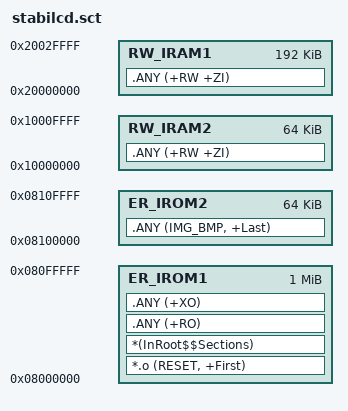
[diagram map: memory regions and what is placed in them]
; *************************************************************
; *** Scatter-Loading Description File generated by uVision ***
; *************************************************************

LR_IROM1 0x08000000 0x00100000  {    ; load region size_region
  ER_IROM1 0x08000000 0x00100000  {  ; load address = execution address
   *.o (RESET, +First)
   *(InRoot$$Sections)
   .ANY (+RO)
   .ANY (+XO)
  }
  ;ER_IROM2 0x08100000 0x00010000  {  ; img
  ; .ANY (IMG_BMP, +Last)
  ;}
  RW_IRAM1 0x20000000 0x00030000  {  ; RW data
   .ANY (+RW +ZI)
  }
  RW_IRAM2 0x10000000 0x00010000  {
   .ANY (+RW +ZI)
  }
}

LR_IROM2 0x08100000 0x00010000  {    ; load region size_region
  ER_IROM2 0x08100000 0x00010000  {  ; img
   .ANY (IMG_BMP, +Last)
  }
}

